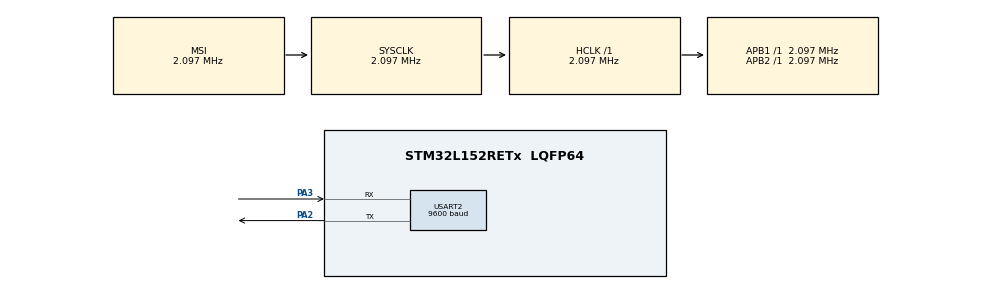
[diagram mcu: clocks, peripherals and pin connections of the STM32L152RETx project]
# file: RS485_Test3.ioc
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Mcu.Family=STM32L1
Mcu.Name=STM32L152RETx
Mcu.Package=LQFP64
NVIC.PriorityGroup=NVIC_PRIORITYGROUP_4
PA2.Mode=Asynchronous
PA2.Signal=USART2_TX
PA3.Mode=Asynchronous
PA3.Signal=USART2_RX
ProjectManager.HeapSize=0x200
ProjectManager.StackSize=0x400
ProjectManager.TargetToolchain=STM32CubeIDE
RCC.AHBFreq_Value=2097000
RCC.APB1Freq_Value=2097000
RCC.APB2Freq_Value=2097000
RCC.HSE_VALUE=24000000
RCC.HSI_VALUE=16000000
RCC.LSE_VALUE=32768
RCC.MSI_VALUE=2097000
RCC.SYSCLKFreq_VALUE=2097000
RCC.VCOOutputFreq_Value=48000000
USART2.BaudRate=9600
USART2.VirtualMode=VM_ASYNC
board=custom

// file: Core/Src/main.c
/* USER CODE BEGIN Header */
/**
  ******************************************************************************
  * @file           : main.c
  * @brief          : Main program body
  ******************************************************************************
  * @attention
  *
  * <h2><center>&copy; Copyright (c) 2021 STMicroelectronics.
  * All rights reserved.</center></h2>
  *
  * This software component is licensed by ST under BSD 3-Clause license,
  * the "License"; You may not use this file except in compliance with the
  * License. You may obtain a copy of the License at:
  *                        opensource.org/licenses/BSD-3-Clause
  *
  ******************************************************************************
  */
/* USER CODE END Header */
#include "main.h"
#include "usart.h"
#include "gpio.h"

/* USER CODE BEGIN Includes */

#include <stm32l1xx_nucleo.h>

/* USER CODE END Includes */

/* USER CODE BEGIN PD */
// #define TRANSMITTER_BOARD
/* USER CODE END PD */

/* USER CODE BEGIN PV */

__IO ITStatus UartReady = RESET;
__IO uint32_t UserButtonStatus = 0;  /* set to 1 after User Button interrupt  */

/* Buffer used for transmission */
uint8_t aTxBuffer[] = " ****UART_TwoBoards_ComIT****  ****UART_TwoBoards_ComIT****  ****UART_TwoBoards_ComIT**** ";

/* Buffer used for reception */
uint8_t aRxBuffer[RXBUFFERSIZE];
/* USER CODE END PV */

void SystemClock_Config(void);
/* USER CODE BEGIN PFP */

static uint16_t Buffercmp(uint8_t* pBuffer1, uint8_t* pBuffer2, uint16_t BufferLength);

/* USER CODE END PFP */

int main(void)
{

  /* MCU Configuration--------------------------------------------------------*/

  /* Reset of all peripherals, Initializes the Flash interface and the Systick. */
  HAL_Init();

  /* USER CODE BEGIN Init */
  BSP_LED_Init(LED2);
  /* USER CODE END Init */

  /* Configure the system clock */
  SystemClock_Config();

  /* Initialize all configured peripherals */
  MX_GPIO_Init();
  MX_USART2_UART_Init();

  /* USER CODE BEGIN 2 */

#ifdef TRANSMITTER_BOARD

  /* Configure User push-button in Interrupt mode */
  BSP_PB_Init(BUTTON_USER, BUTTON_MODE_EXTI);

  /* Wait for User push-button press before starting the Communication.
     In the meantime, LED2 is blinking */
  while(UserButtonStatus == 0)
  {
      /* Toggle LED2*/
      BSP_LED_Toggle(LED2);
      HAL_Delay(100);
  }

  BSP_LED_Off(LED2);

  /* The board sends the message and expects to receive it back */

  /*##-2- Start the transmission process #####################################*/
  /* While the UART in reception process, user can transmit data through
     "aTxBuffer" buffer */
  if(HAL_UART_Transmit_IT(&huart2, (uint8_t*)aTxBuffer, TXBUFFERSIZE)!= HAL_OK)
  {
    Error_Handler();
  }

  /*##-3- Wait for the end of the transfer ###################################*/
  while (UartReady != SET)
  {
  }

  /* Reset transmission flag */
  UartReady = RESET;

  /*##-4- Put UART peripheral in reception process ###########################*/
  if(HAL_UART_Receive_IT(&huart2, (uint8_t *)aRxBuffer, RXBUFFERSIZE) != HAL_OK)
  {
    Error_Handler();
  }

#else

  /* The board receives the message and sends it back */

  /*##-2- Put UART peripheral in reception process ###########################*/
  if(HAL_UART_Receive_IT(&huart2, (uint8_t *)aRxBuffer, RXBUFFERSIZE) != HAL_OK)
  {
    Error_Handler();
  }

  /*##-3- Wait for the end of the transfer ###################################*/
  /* While waiting for message to come from the other board, LED2 is
     blinking according to the following pattern: a double flash every half-second */
  while (UartReady != SET)
  {
      BSP_LED_On(LED2);
      HAL_Delay(100);
      BSP_LED_Off(LED2);
      HAL_Delay(100);
      BSP_LED_On(LED2);
      HAL_Delay(100);
      BSP_LED_Off(LED2);
      HAL_Delay(500);
  }

  /* Reset transmission flag */
  UartReady = RESET;
  BSP_LED_Off(LED2);

  /*##-4- Start the transmission process #####################################*/
  /* While the UART in reception process, user can transmit data through
     "aTxBuffer" buffer */
  if(HAL_UART_Transmit_IT(&huart2, (uint8_t*)aTxBuffer, TXBUFFERSIZE)!= HAL_OK)
  {
    Error_Handler();
  }

#endif /* TRANSMITTER_BOARD */

  /*##-5- Wait for the end of the transfer ###################################*/
  while (UartReady != SET)
  {
  }

  /* Reset transmission flag */
  UartReady = RESET;

  /*##-6- Compare the sent and received buffers ##############################*/
  if(Buffercmp((uint8_t*)aTxBuffer,(uint8_t*)aRxBuffer,RXBUFFERSIZE))
  {
    Error_Handler();
  }

  /* Turn on LED2 if test passes then enter infinite loop */
  BSP_LED_On(LED2);
  /* USER CODE END 2 */

  /* Infinite loop */
  while (1)
  {

  }
}

void SystemClock_Config(void)
{
  RCC_OscInitTypeDef RCC_OscInitStruct = {0};
  RCC_ClkInitTypeDef RCC_ClkInitStruct = {0};

  /** Configure the main internal regulator output voltage
  */
  __HAL_PWR_VOLTAGESCALING_CONFIG(PWR_REGULATOR_VOLTAGE_SCALE1);
  /** Initializes the RCC Oscillators according to the specified parameters
  * in the RCC_OscInitTypeDef structure.
  */
  RCC_OscInitStruct.OscillatorType = RCC_OSCILLATORTYPE_MSI;
  RCC_OscInitStruct.MSIState = RCC_MSI_ON;
  RCC_OscInitStruct.MSICalibrationValue = 0;
  RCC_OscInitStruct.MSIClockRange = RCC_MSIRANGE_5;
  RCC_OscInitStruct.PLL.PLLState = RCC_PLL_NONE;
  if (HAL_RCC_OscConfig(&RCC_OscInitStruct) != HAL_OK)
  {
    Error_Handler();
  }
  /** Initializes the CPU, AHB and APB buses clocks
  */
  RCC_ClkInitStruct.ClockType = RCC_CLOCKTYPE_HCLK|RCC_CLOCKTYPE_SYSCLK
                              |RCC_CLOCKTYPE_PCLK1|RCC_CLOCKTYPE_PCLK2;
  RCC_ClkInitStruct.SYSCLKSource = RCC_SYSCLKSOURCE_MSI;
  RCC_ClkInitStruct.AHBCLKDivider = RCC_SYSCLK_DIV1;
  RCC_ClkInitStruct.APB1CLKDivider = RCC_HCLK_DIV1;
  RCC_ClkInitStruct.APB2CLKDivider = RCC_HCLK_DIV1;

  if (HAL_RCC_ClockConfig(&RCC_ClkInitStruct, FLASH_LATENCY_0) != HAL_OK)
  {
    Error_Handler();
  }
}

/* USER CODE BEGIN 4 */

/**
  * @brief  Tx Transfer completed callback
  * @param  UartHandle: UART handle.
  * @note   This example shows a simple way to report end of IT Tx transfer, and
  *         you can add your own implementation.
  * @retval None
  */
void HAL_UART_TxCpltCallback(UART_HandleTypeDef *UartHandle)
{
  /* Set transmission flag: trasfer complete*/
  UartReady = SET;
}

/**
  * @brief  Rx Transfer completed callback
  * @param  UartHandle: UART handle
  * @note   This example shows a simple way to report end of DMA Rx transfer, and
  *         you can add your own implementation.
  * @retval None
  */
void HAL_UART_RxCpltCallback(UART_HandleTypeDef *UartHandle)
{
  /* Set transmission flag: trasfer complete*/
  UartReady = SET;
}

/**
  * @brief  UART error callbacks
  * @param  UartHandle: UART handle
  * @note   This example shows a simple way to report transfer error, and you can
  *         add your own implementation.
  * @retval None
  */
void HAL_UART_ErrorCallback(UART_HandleTypeDef *UartHandle)
{
    Error_Handler();
}

/**
  * @brief EXTI line detection callbacks
  * @param GPIO_Pin: Specifies the pins connected EXTI line
  * @retval None
  */
void HAL_GPIO_EXTI_Callback(uint16_t GPIO_Pin)
{
  if(GPIO_Pin == USER_BUTTON_PIN)
  {
    UserButtonStatus = 1;
  }
}

/**
  * @brief  Compares two buffers.
  * @param  pBuffer1, pBuffer2: buffers to be compared.
  * @param  BufferLength: buffer's length
  * @retval 0  : pBuffer1 identical to pBuffer2
  *         >0 : pBuffer1 differs from pBuffer2
  */
static uint16_t Buffercmp(uint8_t* pBuffer1, uint8_t* pBuffer2, uint16_t BufferLength)
{
  while (BufferLength--)
  {
    if ((*pBuffer1) != *pBuffer2)
    {
      return BufferLength;
    }
    pBuffer1++;
    pBuffer2++;
  }

  return 0;
}

/* USER CODE END 4 */

void Error_Handler(void)
{
  /* USER CODE BEGIN Error_Handler_Debug */
  /* User can add his own implementation to report the HAL error return state */
	__disable_irq();
	BSP_LED_On(LED2);
	while (1) {
		/* Error if LED2 is slowly blinking (1 sec. period) */
		BSP_LED_Toggle(LED2);
		HAL_Delay(1000);
	}
  /* USER CODE END Error_Handler_Debug */
}

/************************ (C) COPYRIGHT STMicroelectronics *****END OF FILE****/
